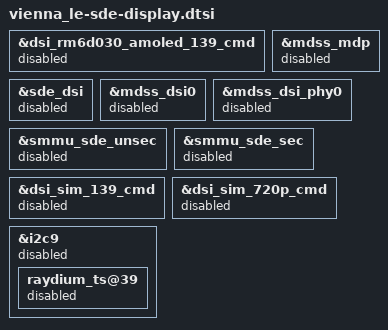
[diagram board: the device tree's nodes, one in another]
// SPDX-License-Identifier: BSD-3-Clause
/*
 * Copyright (c) Qualcomm Technologies, Inc. and/or its subsidiaries.
 */

#include "vienna-sde-display.dtsi"
#include "vienna-sde-display-rcm.dtsi"
#include "vienna-sde-display-wdp.dtsi"
#include "vienna-sde-display-wrd.dtsi"
#include "vienna-sde-display-atp.dtsi"

&dsi_rm6d030_amoled_139_cmd {
	status = "disabled";
};

&mdss_mdp {
	status = "disabled";
};

&sde_dsi {
	status = "disabled";
};

&mdss_dsi0 {
	status = "disabled";
};

&mdss_dsi_phy0 {
	status = "disabled";
};

&smmu_sde_unsec {
	status = "disabled";
};

&smmu_sde_sec {
	status = "disabled";
};

&dsi_sim_139_cmd {
	status = "disabled";
};

&dsi_sim_720p_cmd {
	status = "disabled";
};

&i2c9 {
	status = "disabled";
	raydium_ts@39 {
		status = "disabled";
	};
};

